# STM32G0B1 register map
File version: 1.5
CPU: CM0 r0p1, little endian, MPU, no FPU, 4 interrupt priority bits
Registers are 32-bit, read-write, reset 0x0 unless marked. A register's access mark holds for its fields unless they carry their own. Offsets are from the block's base; [hi:lo] are bit positions; {n}, {i} and the like mark numbered series; 'fields as' and 'values as' point back to an identical list.

## ADC — Analog to Digital Converter
Base 0x40012400
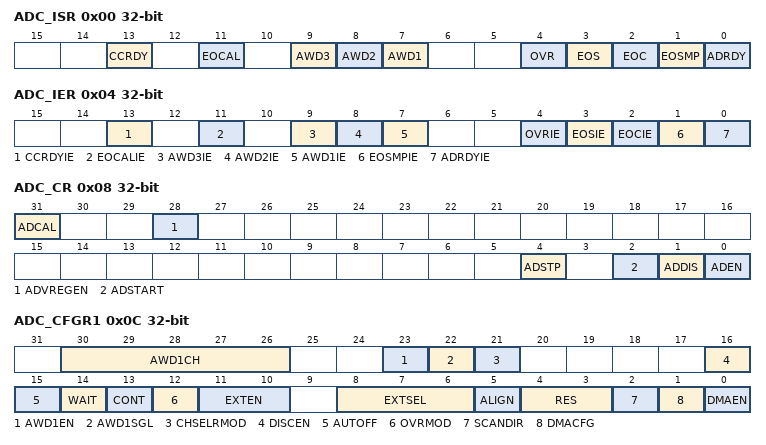
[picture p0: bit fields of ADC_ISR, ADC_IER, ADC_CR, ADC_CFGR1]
0x00 ADC_ISR — ADC interrupt and status register
  [13] CCRDY — Channel Configuration Ready flag This flag bit is set by hardware when the channel configuration is applied after programming to ADC_CHSELR register or changing CHSELRMOD or SCANDIR. It is cleared by software by programming it to it. Note: When the software configures the channels (by programming ADC_CHSELR or changing CHSELRMOD or SCANDIR), it must wait until the CCRDY flag rises before configuring again or starting conversions, otherwise the new configuration (or the START bit) is ignored. Once the flag is asserted, if the software needs to configure again the channels, it must clear the CCRDY flag before proceeding with a new configuration.
    0=Channel configuration update not applied; 1=Channel configuration update is applied
  [11] EOCAL — End Of Calibration flag This bit is set by hardware when calibration is complete. It is cleared by software writing 1 to it.
    0=Calibration is not complete; 1=Calibration is complete
  [9] AWD3 — Analog watchdog 3 flag This bit is set by hardware when the converted voltage crosses the values programmed in ADC_AWD3TR and ADC_AWD3TR registers. It is cleared by software by programming it to 1.
    0=No analog watchdog event occurred (or the flag event was already acknowledged and cleared by software); 1=Analog watchdog event occurred
  [8] AWD2 — Analog watchdog 2 flag This bit is set by hardware when the converted voltage crosses the values programmed in ADC_AWD2TR and ADC_AWD2TR registers. It is cleared by software programming it it.
    values as AWD3
  [7] AWD1 — Analog watchdog 1 flag This bit is set by hardware when the converted voltage crosses the values programmed in ADC_TR1 and ADC_HR1 registers. It is cleared by software by programming it to 1.
    values as AWD3
  [4] OVR — ADC overrun This bit is set by hardware when an overrun occurs, meaning that a new conversion has complete while the EOC flag was already set. It is cleared by software writing 1 to it.
    0=No overrun occurred (or the flag event was already acknowledged and cleared by software); 1=Overrun has occurred
  [3] EOS — End of sequence flag This bit is set by hardware at the end of the conversion of a sequence of channels selected by the CHSEL bits. It is cleared by software writing 1 to it.
    0=Conversion sequence not complete (or the flag event was already acknowledged and cleared by software); 1=Conversion sequence complete
  [2] EOC — End of conversion flag This bit is set by hardware at the end of each conversion of a channel when a new data result is available in the ADC_DR register. It is cleared by software writing 1 to it or by reading the ADC_DR register.
    0=Channel conversion not complete (or the flag event was already acknowledged and cleared by software); 1=Channel conversion complete
  [1] EOSMP — End of sampling flag This bit is set by hardware during the conversion, at the end of the sampling phase.It is cleared by software by programming it to '1'.
    0=Not at the end of the sampling phase (or the flag event was already acknowledged and cleared by software); 1=End of sampling phase reached
  [0] ADRDY — ADC ready This bit is set by hardware after the ADC has been enabled (ADEN = 1) and when the ADC reaches a state where it is ready to accept conversion requests. It is cleared by software writing 1 to it.
    0=ADC not yet ready to start conversion (or the flag event was already acknowledged and cleared by software); 1=ADC is ready to start conversion
0x04 ADC_IER — ADC interrupt enable register
  [13] CCRDYIE — Channel Configuration Ready Interrupt enable This bit is set and cleared by software to enable/disable the channel configuration ready interrupt. Note: The software is allowed to write this bit only when ADSTART bit is cleared to 0 (this ensures that no conversion is ongoing).
    0=Channel configuration ready interrupt disabled; 1=Channel configuration ready interrupt enabled
  [11] EOCALIE — End of calibration interrupt enable This bit is set and cleared by software to enable/disable the end of calibration interrupt. Note: The software is allowed to write this bit only when ADSTART bit is cleared to 0 (this ensures that no conversion is ongoing).
    0=End of calibration interrupt disabled; 1=End of calibration interrupt enabled
  [9] AWD3IE — Analog watchdog 3 interrupt enable This bit is set and cleared by software to enable/disable the analog watchdog interrupt. Note: The Software is allowed to write this bit only when ADSTART bit is cleared to 0 (this ensures that no conversion is ongoing).
    0=Analog watchdog interrupt disabled; 1=Analog watchdog interrupt enabled
  [8] AWD2IE — Analog watchdog 2 interrupt enable This bit is set and cleared by software to enable/disable the analog watchdog interrupt. Note: The Software is allowed to write this bit only when ADSTART bit is cleared to 0 (this ensures that no conversion is ongoing).
    values as AWD3IE
  [7] AWD1IE — Analog watchdog 1 interrupt enable This bit is set and cleared by software to enable/disable the analog watchdog interrupt. Note: The Software is allowed to write this bit only when ADSTART bit is cleared to 0 (this ensures that no conversion is ongoing).
    values as AWD3IE
  [4] OVRIE — Overrun interrupt enable This bit is set and cleared by software to enable/disable the overrun interrupt. Note: The software is allowed to write this bit only when ADSTART bit is cleared to 0 (this ensures that no conversion is ongoing).
    0=Overrun interrupt disabled; 1=Overrun interrupt enabled. An interrupt is generated when the OVR bit is set.
  [3] EOSIE — End of conversion sequence interrupt enable This bit is set and cleared by software to enable/disable the end of sequence of conversions interrupt. Note: The software is allowed to write this bit only when ADSTART bit is cleared to 0 (this ensures that no conversion is ongoing).
    0=EOS interrupt disabled; 1=EOS interrupt enabled. An interrupt is generated when the EOS bit is set.
  [2] EOCIE — End of conversion interrupt enable This bit is set and cleared by software to enable/disable the end of conversion interrupt. Note: The software is allowed to write this bit only when ADSTART bit is cleared to 0 (this ensures that no conversion is ongoing).
    0=EOC interrupt disabled; 1=EOC interrupt enabled. An interrupt is generated when the EOC bit is set.
  [1] EOSMPIE — End of sampling flag interrupt enable This bit is set and cleared by software to enable/disable the end of the sampling phase interrupt. Note: The software is allowed to write this bit only when ADSTART bit is cleared to 0 (this ensures that no conversion is ongoing).
    0=EOSMP interrupt disabled; 1=EOSMP interrupt enabled. An interrupt is generated when the EOSMP bit is set.
  [0] ADRDYIE — ADC ready interrupt enable This bit is set and cleared by software to enable/disable the ADC Ready interrupt. Note: The software is allowed to write this bit only when ADSTART bit is cleared to 0 (this ensures that no conversion is ongoing).
    0=ADRDY interrupt disabled; 1=ADRDY interrupt enabled. An interrupt is generated when the ADRDY bit is set.
0x08 ADC_CR — ADC control register
  [31] ADCAL — ADC calibration This bit is set by software to start the calibration of the ADC. It is cleared by hardware after calibration is complete. Note: The software is allowed to set ADCAL only when the ADC is disabled (ADCAL = 0, ADSTART = 0, ADSTP = 0, ADDIS = 0 and ADEN = 0). The software is allowed to update the calibration factor by writing ADC_CALFACT only when ADEN = 1 and ADSTART = 0 (ADC enabled and no conversion is ongoing).
    0=Calibration complete; 1=Write 1 to calibrate the ADC. Read at 1 means that a calibration is in progress.
  [28] ADVREGEN — ADC Voltage Regulator Enable This bit is set by software, to enable the ADC internal voltage regulator. The voltage regulator output is available after tADCVREG_SETUP. It is cleared by software to disable the voltage regulator. It can be cleared only if ADEN is et to 0. Note: The software is allowed to program this bit field only when the ADC is disabled (ADCAL = 0, ADSTART = 0, ADSTP = 0, ADDIS = 0 and ADEN = 0).
    0=ADC voltage regulator disabled; 1=ADC voltage regulator enabled
  [4] ADSTP — ADC stop conversion command This bit is set by software to stop and discard an ongoing conversion (ADSTP Command). It is cleared by hardware when the conversion is effectively discarded and the ADC is ready to accept a new start conversion command. Note: Setting ADSTP to '1' is only effective when ADSTART = 1 and ADDIS = 0 (ADC is enabled and may be converting and there is no pending request to disable the ADC)
    0=No ADC stop conversion command ongoing; 1=Write 1 to stop the ADC. Read 1 means that an ADSTP command is in progress.
  [2] ADSTART — ADC start conversion command This bit is set by software to start ADC conversion. Depending on the EXTEN [1:0] configuration bits, a conversion either starts immediately (software trigger configuration) or once a hardware trigger event occurs (hardware trigger configuration). It is cleared by hardware: In single conversion mode (CONT = 0, DISCEN = 0), when software trigger is selected (EXTEN = 00): at the assertion of the end of Conversion Sequence (EOS) flag. In discontinuous conversion mode(CONT = 0, DISCEN = 1), when the software trigger is selected (EXTEN = 00): at the assertion of the end of Conversion (EOC) flag. In all other cases: after the execution of the ADSTP command, at the same time as the ADSTP bit is cleared by hardware. Note: The software is allowed to set ADSTART only when ADEN = 1 and ADDIS = 0 (ADC is enabled and there is no pending request to disable the ADC). After writing to ADC_CHSELR register or changing CHSELRMOD or SCANDIRW, it is mandatory to wait until CCRDY flag is asserted before setting ADSTART, otherwise, the value written to ADSTART is ignored.
    0=No ADC conversion is ongoing; 1=Write 1 to start the ADC. Read 1 means that the ADC is operating and may be converting.
  [1] ADDIS — ADC disable command This bit is set by software to disable the ADC (ADDIS command) and put it into power-down state (OFF state). It is cleared by hardware once the ADC is effectively disabled (ADEN is also cleared by hardware at this time). Note: Setting ADDIS to '1' is only effective when ADEN = 1 and ADSTART = 0 (which ensures that no conversion is ongoing)
    0=No ADDIS command ongoing; 1=Write 1 to disable the ADC. Read 1 means that an ADDIS command is in progress.
  [0] ADEN — ADC enable command This bit is set by software to enable the ADC. The ADC is effectively ready to operate once the ADRDY flag has been set. It is cleared by hardware when the ADC is disabled, after the execution of the ADDIS command. Note: The software is allowed to set ADEN only when all bits of ADC_CR registers are 0 (ADCAL = 0, ADSTP = 0, ADSTART = 0, ADDIS = 0 and ADEN = 0)
    0=ADC is disabled (OFF state); 1=Write 1 to enable the ADC
0x0C ADC_CFGR1 — ADC configuration register 1
  [30:26] AWD1CH — Analog watchdog channel selection These bits are set and cleared by software. They select the input channel to be guarded by the analog watchdog. ..... Others: Reserved Note: The channel selected by the AWDCH[4:0] bits must be also set into the CHSELR register. The software is allowed to write this bit only when ADSTART bit is cleared to 0 (this ensures that no conversion is ongoing).
    0=ADC analog input Channel 0 monitored by AWD; 1=ADC analog input Channel 1 monitored by AWD; 17=ADC analog input Channel 17 monitored by AWD; 18=ADC analog input Channel 18 monitored by AWD
  [23] AWD1EN — Analog watchdog enable This bit is set and cleared by software. Note: The software is allowed to write this bit only when ADSTART bit is cleared to 0 (this ensures that no conversion is ongoing).
    0=Analog watchdog 1 disabled; 1=Analog watchdog 1 enabled
  [22] AWD1SGL — Enable the watchdog on a single channel or on all channels This bit is set and cleared by software to enable the analog watchdog on the channel identified by the AWDCH[4:0] bits or on all the channels Note: The software is allowed to write this bit only when ADSTART bit is cleared to 0 (this ensures that no conversion is ongoing).
    0=Analog watchdog 1 enabled on all channels; 1=Analog watchdog 1 enabled on a single channel
  [21] CHSELRMOD — Mode selection of the ADC_CHSELR register This bit is set and cleared by software to control the ADC_CHSELR feature: Note: The software is allowed to write this bit only when ADSTART bit is cleared to 0 (this ensures that no conversion is ongoing). If CCRDY is not yet asserted after channel configuration (writing ADC_CHSELR register or changing CHSELRMOD or SCANDIR), the value written to this bit is ignored.
    0=Each bit of the ADC_CHSELR register enables an input; 1=ADC_CHSELR register is able to sequence up to 8 channels
  [16] DISCEN — Discontinuous mode This bit is set and cleared by software to enable/disable discontinuous mode. Note: It is not possible to have both discontinuous mode and continuous mode enabled: it is forbidden to set both bits DISCEN = 1 and CONT = 1. The software is allowed to write this bit only when ADSTART bit is cleared to 0 (this ensures that no conversion is ongoing).
    0=Discontinuous mode disabled; 1=Discontinuous mode enabled
  [15] AUTOFF — Auto-off mode This bit is set and cleared by software to enable/disable auto-off mode.. Note: The software is allowed to write this bit only when ADSTART bit is cleared to 0 (this ensures that no conversion is ongoing).
    0=Auto-off mode disabled; 1=Auto-off mode enabled
  [14] WAIT — Wait conversion mode This bit is set and cleared by software to enable/disable wait conversion mode.. Note: The software is allowed to write this bit only when ADSTART bit is cleared to 0 (this ensures that no conversion is ongoing).
    0=Wait conversion mode off; 1=Wait conversion mode on
  [13] CONT — Single / continuous conversion mode This bit is set and cleared by software. If it is set, conversion takes place continuously until it is cleared. Note: It is not possible to have both discontinuous mode and continuous mode enabled: it is forbidden to set both bits DISCEN = 1 and CONT = 1. The software is allowed to write this bit only when ADSTART bit is cleared to 0 (this ensures that no conversion is ongoing).
    0=Single conversion mode; 1=Continuous conversion mode
  [12] OVRMOD — Overrun management mode This bit is set and cleared by software and configure the way data overruns are managed. Note: The software is allowed to write this bit only when ADSTART bit is cleared to 0 (this ensures that no conversion is ongoing).
    0=ADC_DR register is preserved with the old data when an overrun is detected; 1=ADC_DR register is overwritten with the last conversion result when an overrun is detected
  [11:10] EXTEN — External trigger enable and polarity selection These bits are set and cleared by software to select the external trigger polarity and enable the trigger. Note: The software is allowed to write this bit only when ADSTART bit is cleared to 0 (this ensures that no conversion is ongoing).
    0=Hardware trigger detection disabled (conversions can be started by software); 1=Hardware trigger detection on the rising edge; 2=Hardware trigger detection on the falling edge; 3=Hardware trigger detection on both the rising and falling edges
  [8:6] EXTSEL — External trigger selection These bits select the external event used to trigger the start of conversion (refer to External triggers for details): Note: The software is allowed to write this bit only when ADSTART bit is cleared to 0 (this ensures that no conversion is ongoing).
    {v}=TRG{v} (v=0..7)
  [5] ALIGN — Data alignment This bit is set and cleared by software to select right or left alignment. Refer to Data alignment and resolution (oversampling disabled: OVSE = 0) on page 401 Note: The software is allowed to write this bit only when ADSTART bit is cleared to 0 (this ensures that no conversion is ongoing).
    0=Right alignment; 1=Left alignment
  [4:3] RES — Data resolution These bits are written by software to select the resolution of the conversion. Note: The software is allowed to write these bits only when ADEN = 0.
    0=12 bits; 1=10 bits; 2=8 bits; 3=6 bits
  [2] SCANDIR — Scan sequence direction This bit is set and cleared by software to select the direction in which the channels is scanned in the sequence. It is effective only if CHSELMOD bit is cleared to 0. Note: The software is allowed to write this bit only when ADSTART bit is cleared to 0 (this ensures that no conversion is ongoing). If CCRDY is not yet asserted after channel configuration (writing ADC_CHSELR register or changing CHSELRMOD or SCANDIR), the value written to this bit is ignored.
    0=Upward scan (from CHSEL0 to CHSEL18); 1=Backward scan (from CHSEL18 to CHSEL0)
  [1] DMACFG — Direct memory access configuration This bit is set and cleared by software to select between two DMA modes of operation and is effective only when DMAEN = 1. For more details, refer to page 403 Note: The software is allowed to write this bit only when ADSTART bit is cleared to 0 (this ensures that no conversion is ongoing).
    0=DMA one shot mode selected; 1=DMA circular mode selected
  [0] DMAEN — Direct memory access enable This bit is set and cleared by software to enable the generation of DMA requests. This allows the DMA controller to be used to manage automatically the converted data. For more details, refer to . Note: The software is allowed to write this bit only when ADSTART bit is cleared to 0 (this ensures that no conversion is ongoing).
    0=DMA disabled; 1=DMA enabled
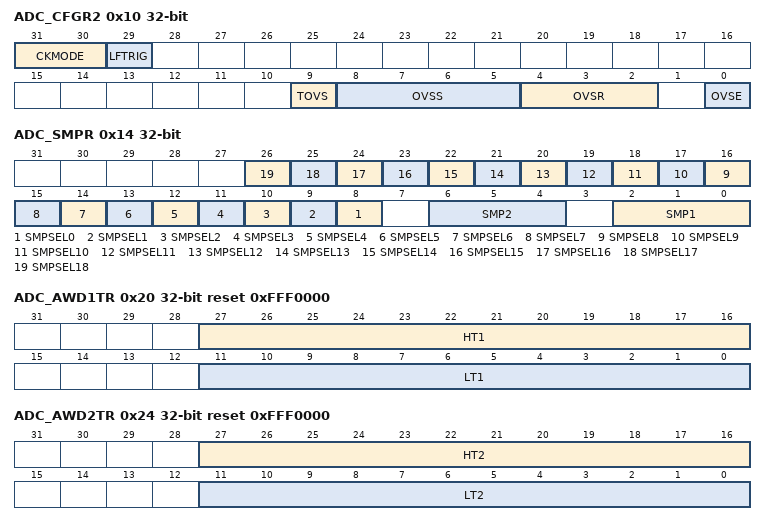
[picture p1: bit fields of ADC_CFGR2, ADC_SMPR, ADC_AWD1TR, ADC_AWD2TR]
0x10 ADC_CFGR2 — ADC configuration register 2
  [31:30] CKMODE — ADC clock mode These bits are set and cleared by software to define how the analog ADC is clocked: In all synchronous clock modes, there is no jitter in the delay from a timer trigger to the start of a conversion. Note: The software is allowed to write these bits only when the ADC is disabled (ADCAL = 0, ADSTART = 0, ADSTP = 0, ADDIS = 0 and ADEN = 0).
    0=ADCCLK (Asynchronous clock mode), generated at product level (refer to RCC section); 1=PCLK/2 (Synchronous clock mode); 2=PCLK/4 (Synchronous clock mode); 3=PCLK (Synchronous clock mode). This configuration must be enabled only if PCLK has a 50% duty clock cycle (APB prescaler configured inside the RCC must be bypassed and the system clock must by 50% duty cycle)
  [29] LFTRIG — Low frequency trigger mode enable This bit is set and cleared by software. Note: The software is allowed to write this bit only when ADSTART bit is cleared to 0 (this ensures that no conversion is ongoing).
    0=Low Frequency Trigger Mode disabled; 1=Low Frequency Trigger Mode enabled
  [9] TOVS — Triggered Oversampling This bit is set and cleared by software. Note: The software is allowed to write this bit only when ADSTART = 0 (which ensures that no conversion is ongoing).
    0=All oversampled conversions for a channel are done consecutively after a trigger; 1=Each oversampled conversion for a channel needs a trigger
  [8:5] OVSS — Oversampling shift This bit is set and cleared by software. Others: Reserved Note: The software is allowed to write this bit only when ADSTART = 0 (which ensures that no conversion is ongoing).
    0=No shift; 1=Shift 1-bit; {v}=Shift {v}-bits (v=2..8)
  [4:2] OVSR — Oversampling ratio This bit filed defines the number of oversampling ratio. Note: The software is allowed to write this bit only when ADSTART = 0 (which ensures that no conversion is ongoing).
    0=2x; 1=4x; 2=8x; 3=16x; 4=32x; 5=64x; 6=128x; 7=256x
  [0] OVSE — Oversampler Enable This bit is set and cleared by software. Note: Software is allowed to write this bit only when ADSTART = 0 (which ensures that no conversion is ongoing).
    0=Oversampler disabled; 1=Oversampler enabled
0x14 ADC_SMPR — ADC sampling time register
  [n+8] SMPSEL{n} (n=0..18) — Channel-x sampling time selection These bits are written by software to define which sampling time is used. Note: The software is allowed to write this bit only when ADSTART = 0 (which ensures that no conversion is ongoing).
    0=Sampling time of CHANNELx use the setting of SMP1[2:0] register; 1=Sampling time of CHANNELx use the setting of SMP2[2:0] register
  [6:4] SMP2 — Sampling time selection 2 These bits are written by software to select the sampling time that applies to all channels. Note: The software is allowed to write this bit only when ADSTART = 0 (which ensures that no conversion is ongoing).
    0=1.5 ADC clock cycles; 1=3.5 ADC clock cycles; 2=7.5 ADC clock cycles; 3=12.5 ADC clock cycles; 4=19.5 ADC clock cycles; 5=39.5 ADC clock cycles; 6=79.5 ADC clock cycles; 7=160.5 ADC clock cycles
  [2:0] SMP1 — Sampling time selection 1 These bits are written by software to select the sampling time that applies to all channels. Note: The software is allowed to write this bit only when ADSTART = 0 (which ensures that no conversion is ongoing).
    values as SMP2
0x20 ADC_AWD1TR reset 0xFFF0000 — ADC watchdog threshold register
  [27:16] HT1 — Analog watchdog 1 higher threshold These bits are written by software to define the higher threshold for the analog watchdog. Refer to ADC_AWDxTR) on page 407.
  [11:0] LT1 — Analog watchdog 1 lower threshold These bits are written by software to define the lower threshold for the analog watchdog. Refer to ADC_AWDxTR) on page 407.
0x24 ADC_AWD2TR reset 0xFFF0000 — ADC watchdog threshold register
  [27:16] HT2 — Analog watchdog 2 higher threshold These bits are written by software to define the higher threshold for the analog watchdog. Refer to ADC_AWDxTR) on page 407.
  [11:0] LT2 — Analog watchdog 2 lower threshold These bits are written by software to define the lower threshold for the analog watchdog. Refer to ADC_AWDxTR) on page 407.
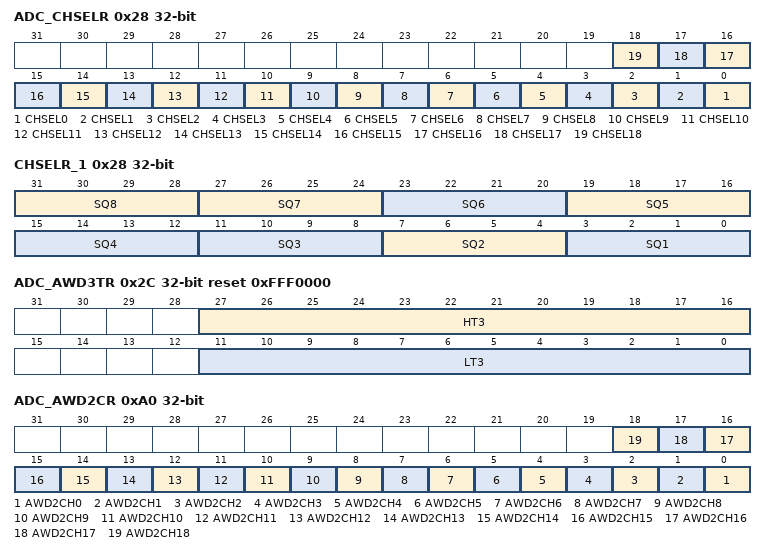
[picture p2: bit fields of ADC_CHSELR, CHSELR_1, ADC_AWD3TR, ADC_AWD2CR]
0x28 ADC_CHSELR — ADC channel selection register [alternate]
  [all] fields
    0=Input Channel-x is not selected for conversion; 1=Input Channel-x is selected for conversion
  [n] CHSEL{n} (n=0..18) — Channel-x selection These bits are written by software and define which channels are part of the sequence of channels to be converted. Note: The software is allowed to write this bit only when ADSTART = 0 (which ensures that no conversion is ongoing). If CCRDY is not yet asserted after channel configuration (writing ADC_CHSELR register or changing CHSELRMOD or SCANDIR), the value written to this bit is ignored.
0x28 CHSELR_1 (alternate view of ADC_CHSELR) — channel selection register CHSELRMOD = 1 in ADC_CFGR1
  [31:28] SQ8 — 8th conversion of the sequence These bits are programmed by software with the channel number (0...14) assigned to the 8th conversion of the sequence. 0b1111 indicates the end of the sequence. When 0b1111 (end of sequence) is programmed to the lower sequence channels, these bits are ignored. ... Note: The software is allowed to write this bit only when ADSTART = 0 (which ensures that no conversion is ongoing).
    0=CH0; 1=CH1; 12=CH12; 13=CH13; 14=CH14; 15=No channel selected (End of sequence)
  [4n-1:4n-4] SQ{n} (n=4..7) — {n}th conversion of the sequence These bits are programmed by software with the channel number (0...14) assigned to the 8th conversion of the sequence. 0b1111 indicates end of the sequence. When 0b1111 (end of sequence) is programmed to the lower sequence channels, these bits are ignored. Refer to SQ8[3:0] for a definition of channel selection. Note: The software is allowed to write this bit only when ADSTART = 0 (which ensures that no conversion is ongoing).
  [11:8] SQ3 — 3rd conversion of the sequence These bits are programmed by software with the channel number (0...14) assigned to the 8th conversion of the sequence. 0b1111 indicates end of the sequence. When 0b1111 (end of sequence) is programmed to the lower sequence channels, these bits are ignored. Refer to SQ8[3:0] for a definition of channel selection. Note: The software is allowed to write this bit only when ADSTART = 0 (which ensures that no conversion is ongoing).
  [7:4] SQ2 — 2nd conversion of the sequence These bits are programmed by software with the channel number (0...14) assigned to the 8th conversion of the sequence. 0b1111 indicates end of the sequence. When 0b1111 (end of sequence) is programmed to the lower sequence channels, these bits are ignored. Refer to SQ8[3:0] for a definition of channel selection. Note: The software is allowed to write this bit only when ADSTART = 0 (which ensures that no conversion is ongoing).
  [3:0] SQ1 — 1st conversion of the sequence These bits are programmed by software with the channel number (0...14) assigned to the 8th conversion of the sequence. 0b1111 indicates end of the sequence. When 0b1111 (end of sequence) is programmed to the lower sequence channels, these bits are ignored. Refer to SQ8[3:0] for a definition of channel selection. Note: The software is allowed to write this bit only when ADSTART = 0 (which ensures that no conversion is ongoing).
0x2C ADC_AWD3TR reset 0xFFF0000 — ADC watchdog threshold register
  [27:16] HT3 — Analog watchdog 3 higher threshold These bits are written by software to define the higher threshold for the analog watchdog. Refer to ADC_AWDxTR) on page 407.
  [11:0] LT3 — Analog watchdog 3lower threshold These bits are written by software to define the lower threshold for the analog watchdog. Refer to ADC_AWDxTR) on page 407.
0x40 ADC_DR ro — ADC data register
  [15:0] DATA — Converted data These bits are read-only. They contain the conversion result from the last converted channel. The data are left- or right-aligned as shown in OVSE = 0) on page 401. Just after a calibration is complete, DATA[6:0] contains the calibration factor.
0xA0 ADC_AWD2CR — ADC Analog Watchdog 2 Configuration register
  [all] fields
    0=ADC analog channel-x is not monitored by AWD2; 1=ADC analog channel-x is monitored by AWD2
  [n] AWD2CH{n} (n=0..18) — Analog watchdog channel selection These bits are set and cleared by software. They enable and select the input channels to be guarded by analog watchdog 2 (AWD2). Note: The channels selected through ADC_AWD2CR must be also configured into the ADC_CHSELR registers. Refer to SQ8[3:0] for a definition of channel selection. The software is allowed to write this bit only when ADSTART = 0 (which ensures that no conversion is ongoing).
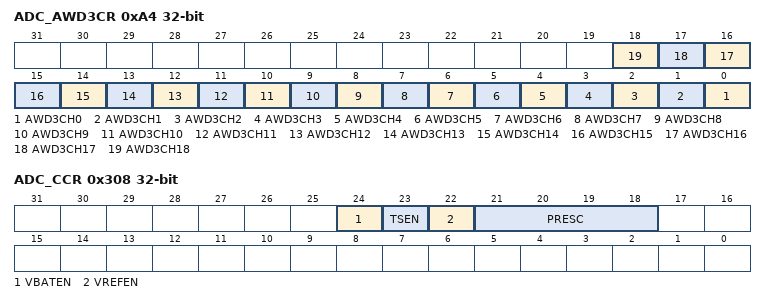
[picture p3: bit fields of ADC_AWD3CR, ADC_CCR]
0xA4 ADC_AWD3CR — ADC Analog Watchdog 3 Configuration register
  [all] fields
    0=ADC analog channel-x is not monitored by AWD3; 1=ADC analog channel-x is monitored by AWD3
  [n] AWD3CH{n} (n=0..18) — Analog watchdog channel selection These bits are set and cleared by software. They enable and select the input channels to be guarded by analog watchdog 3 (AWD3). Note: The channels selected through ADC_AWD3CR must be also configured into the ADC_CHSELR registers. Refer to SQ8[3:0] for a definition of channel selection. The software is allowed to write this bit only when ADSTART=0 (which ensures that no conversion is ongoing).
0xB4 ADC_CALFACT — ADC Calibration factor
  [6:0] CALFACT — Calibration factor These bits are written by hardware or by software. Once a calibration is complete, they are updated by hardware with the calibration factors. Software can write these bits with a new calibration factor. If the new calibration factor is different from the current one stored into the analog ADC, it is then applied once a new calibration is launched. Just after a calibration is complete, DATA[6:0] contains the calibration factor. Note: Software can write these bits only when ADEN=1 (ADC is enabled and no calibration is ongoing and no conversion is ongoing). Refer to SQ8[3:0] for a definition of channel selection.
0x308 ADC_CCR — ADC common configuration register
  [24] VBATEN — VBAT enable This bit is set and cleared by software to enable/disable the VBAT channel. Note: The software is allowed to write this bit only when ADSTART = 0 (which ensures that no conversion is ongoing)
    0=VBAT channel disabled, DAC_OUT2 connected to ADC channel 14; 1=VBAT channel enabled
  [23] TSEN — Temperature sensor enable This bit is set and cleared by software to enable/disable the temperature sensor. Note: Software is allowed to write this bit only when ADSTART = 0 (which ensures that no conversion is ongoing).
    0=Temperature sensor disabled, DAC_OUT1 connected to ADC channel 12; 1=Temperature sensor enabled
  [22] VREFEN — VREFINT enable This bit is set and cleared by software to enable/disable the VREFINT. Note: Software is allowed to write this bit only when ADSTART = 0 (which ensures that no conversion is ongoing).
    0=VREFINT disabled; 1=VREFINT enabled
  [21:18] PRESC — ADC prescaler Set and cleared by software to select the frequency of the clock to the ADC. Other: Reserved Note: Software is allowed to write these bits only when the ADC is disabled (ADCAL = 0, ADSTART = 0, ADSTP = 0, ADDIS = 0 and ADEN = 0).
    0=input ADC clock not divided; 1=input ADC clock divided by 2; 2=input ADC clock divided by 4; 3=input ADC clock divided by 6; 4=input ADC clock divided by 8; 5=input ADC clock divided by 10; 6=input ADC clock divided by 12; 7=input ADC clock divided by 16; 8=input ADC clock divided by 32; 9=input ADC clock divided by 64; 10=input ADC clock divided by 128; 11=input ADC clock divided by 256

## Notices in the file
Copyright (c) 2022 STMicroelectronics.
SPDX-License-Identifier: Apache-2.0
Licensed under the Apache License, Version 2.0 (the "License");
you may not use this file except in compliance with the License.
You may obtain a copy of the License at
http://www.apache.org/licenses/LICENSE-2.0
Unless required by applicable law or agreed to in writing, software
distributed under the License is distributed on an "AS IS" BASIS,
WITHOUT WARRANTIES OR CONDITIONS OF ANY KIND, either express or implied.
See the License for the specific language governing permissions and
limitations under the License.
